# Template register map
Vendor: VendorName Co.Ltd; Series: SeriesName; File version: 1.2
CPU: CM7 r0p1, little endian, MPU, FPU, 4 interrupt priority bits
Registers are 32-bit, read-write, no defined reset value unless marked. A register's access mark holds for its fields unless they carry their own. Offsets are from the block's base; [hi:lo] are bit positions; {n}, {i} and the like mark numbered series; 'fields as' and 'values as' point back to an identical list.

## SDFM1 — Sigma Delta Filter Module 1
Base 0x40014000
Same registers: SDFM2 0x40015000, SDFM3 0x40016000, SDFM4 0x40017000
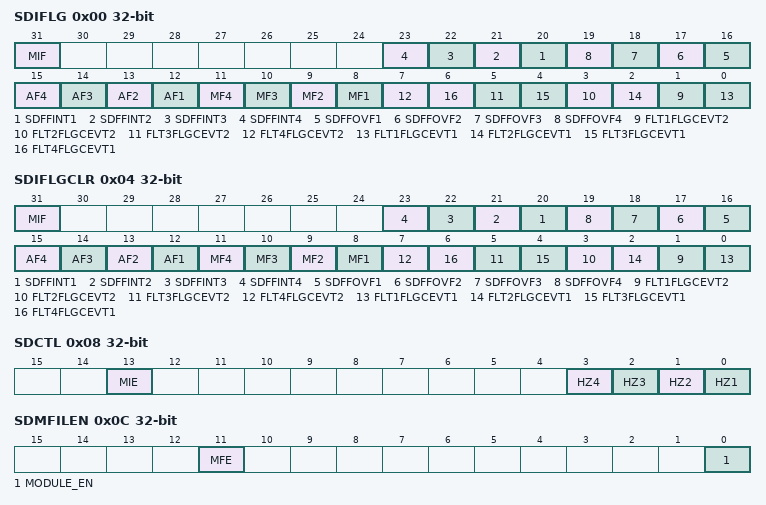
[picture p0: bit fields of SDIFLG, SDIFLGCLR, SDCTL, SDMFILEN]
0x00 SDIFLG ro — SDFM interrupt flag register
  [31] MIF — SDFM MIF bit: set whenever any error interrupt
  [n+19] SDFFINT{n} (n=1..4) — SDFM SDFFINT{n} bit: SDFIFO data ready interrupt for Ch{n}
  [n+15] SDFFOVF{n} (n=1..4) — SDFM SDFFOVF{n} bit: FIFO overflow flag for Ch{n}
  [n+11] AF{n} (n=1..4) — SDFM AF{n} bit: acknowledge flag for filter {n}
  [n+7] MF{n} (n=1..4) — SDFM MF{n} bit: modulator failure for filter {n}
  [2n-1] FLT{n}FLGCEVT2 (n=1..4) — SDFM FLT{n}FLGCEVT2 bit: low-level interrupt flag for Ch{n}
  [2n-2] FLT{n}FLGCEVT1 (n=1..4) — SDFM FLT{n}FLGCEVT1 bit: high-level interrupt flag for Ch{n}
0x04 SDIFLGCLR — SDFM interrupt flag clear register
  [31] MIF — SDFM MIF bit: flag-clear bit for SDFM master interrupt flag
  [n+19] SDFFINT{n} (n=1..4) — SDFM SDFFINT{n} bit: SDFIFO data ready interrupt flag-clear bit for Ch{n}
  [n+15] SDFFOVF{n} (n=1..4) — SDFM SDFFOVF{n} bit: SDFIFO overflow clear Ch{n}
  [n+11] AF{n} (n=1..4) — SDFM AF{n} bit: flag clear bit for acknowledge flag for filter {n}
  [n+7] MF{n} (n=1..4) — SDFM MF{n} bit: flag clear bit for MF{n}
  [2n-1] FLT{n}FLGCEVT2 (n=1..4) — SDFM FLT{n}FLGCEVT2 bit: flag clear bit for IFL{n}
  [2n-2] FLT{n}FLGCEVT1 (n=1..4) — SDFM FLT{n}FLGCEVT1 bit: flag clear bit for IFH{n}
0x08 SDCTL — SDFM control register
  [13] MIE — SDFM MIE bit: master SDy_ERR interrupt enable
  [n-1] HZ{n} (n=1..4) — SDFM HZ{n} bit: flag clear bit for HZ{n}
0x0C SDMFILEN — SDFM master filter enable register
  [11] MFE — SDFM MFE bit: master filter enable
  [0] MODULE_EN — SDFM MODULE_EN bit: input enable signal of module clock and bit stream
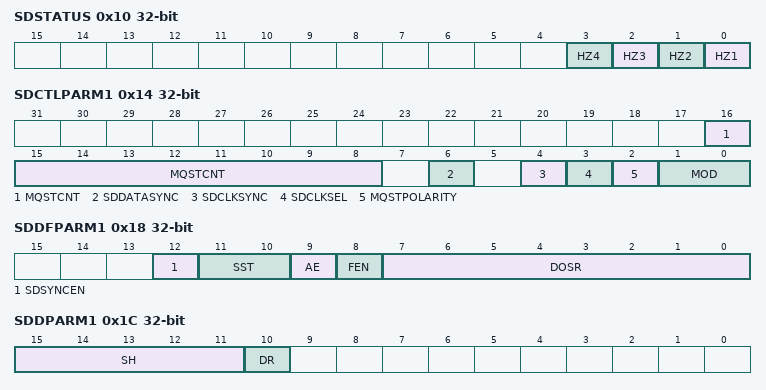
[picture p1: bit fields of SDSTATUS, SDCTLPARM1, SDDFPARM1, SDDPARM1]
0x10 SDSTATUS ro — SDFM status register
  [n-1] HZ{n} (n=1..4) — SDFM HZ{n} bit: high-level threshold crossing flag Ch{n}
0x14 SDCTLPARM1 — SDFM channel 1 parameter control register
  [16:8] MQSTCNT — SDFM MQSTCNT[8:0] bit: specify the maximum value of counter that uses SDFMCLK decoding
  [6] SDDATASYNC — SDFM SDDATASYNC bit: whether modulated bit stream of channel 1 will be filtered to eliminate noise
  [4] SDCLKSYNC — SDFM SDCLKSYNC bit: whether modulated clock of channel 1 will be filtered to eliminate noise
  [3] SDCLKSEL — SDFM SDCLKSEL bit: modulated clock of channel 1 select
  [2] MQSTPOLARITY — SDFM MQSTPOLARITY bit: protocol standard on which Manchester decoding is based
  [1:0] MOD — SDFM MOD[1:0] bit: modulator clock modes
0x18 SDDFPARM1 — SDFM channel 1 data-filter control register
  [12] SDSYNCEN — SDFM SDSYNCEN bit: PWM synchronization of data filter of channel 1
  [11:10] SST — SDFM SST[1:0] bit: data filter structure of channel 1
  [9] AE — SDFM AE bit: data filter acknowledge enable of channel 1
  [8] FEN — SDFM FEN bit: data filter enable of channel 1
  [7:0] DOSR — SDFM DOSR[7:0] bit: data filter oversampling ratio of channel 1
0x1C SDDPARM1 — SDFM channel 1 data-filter paramenter control register
  [15:11] SH — SDFM SH[4:0] bit: shift control of channel 1
  [10] DR — SDFM DR bit: data filter data representation of channel 1
0x20 SDFLT1CMPH1 — SDFM channel 1 high limit register 1
  [14:0] HLT — SDFM HLT[14:0] bit: high limit register 1 compare with the comparator filter of channel 1 output
0x24 SDFLT1CMPL1 — SDFM channel 1 low limit register 1
  [14:0] LLT — SDFM LLT[14:0] bit: low limit register 1 compare with the comparator filter of channel 1 output
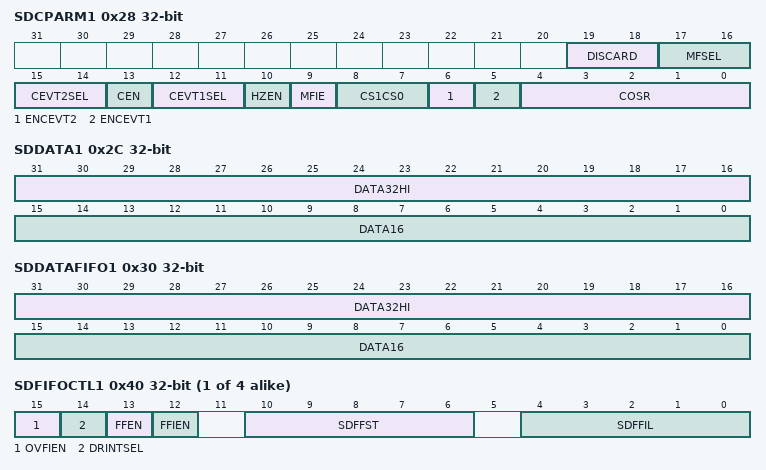
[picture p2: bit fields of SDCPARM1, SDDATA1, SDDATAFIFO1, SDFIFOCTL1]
0x28 SDCPARM1 — SDFM channel 1 comparator filter control register
  [19:18] DISCARD — SDFM DISCARD[1:0] bit: select the first few pieces of data not participating comparation
  [17:16] MFSEL — SDFM MFSEL[1:0] bit: clock not reverse detection window size select
  [15:14] CEVT2SEL — SDFM CEVT2SEL[1:0] bit: comparator filter of channel 1 CEVT2 select
  [13] CEN — SDFM CEN bit: comparator filter of channel 1 enable
  [12:11] CEVT1SEL — SDFM CEVT1SEL[1:0] bit: comparator filter of channel 1 CEVT1 select
  [10] HZEN — SDFM HZEN bit: high level threshold crossing output enable of channel 1
  [9] MFIE — SDFM MFIE bit: modulator failure interrupt enable of channel 1
  [8:7] CS1CS0 — SDFM CS1CS0[1:0] bit: comparator filter of channel 1 structure
  [6] ENCEVT2 — SDFM ENCEVT2 bit: comparator filter of channel 1 CEVT2 interrupt enable
  [5] ENCEVT1 — SDFM ENCEVT1 bit: comparator filter of channel 1 CEVT1 interrupt enable
  [4:0] COSR — SDFM COSR[4:0] bit: comparator oversampling ratio of channel 1
0x2C SDDATA1 ro — SDFM channel 1 data-filter register
  [31:16] DATA32HI — SDFM DATA32HI[15:0] bit: high 16 bit of storing result in 32 bit mode
  [15:0] DATA16 — SDFM DATA16[15:0] bit: low 16 bit of storing result in 32 bit mode
0x30 SDDATAFIFO1 ro — SDFM channel 1 data-fliter FIFO register
  fields as SDDATA1
0x34 SDCDATA1 ro — SDFM channel 1 comparator filter result register
  [15:0] DATA16 — SDFM DATA16[15:0] bit: filtering result of comparator filter of channel 1
{0x0+0x38*i} SDFLT{i}CMPH2 (i=1..4) — SDFM channel {i} high limit register 2
  [14:0] HLT — SDFM HLT[14:0] bit: high limit register 2 compare with the comparator filter of channel {i} output
{0x4+0x38*i} SDFLT{i}CMPHZ (i=1..4) — SDFM channel {i} Z limit register
  [14:0] HLTZ — SDFM HLTZ[14:0] bit: Z limit register compare with the comparator filter of channel {i} output
{0x8+0x38*i} SDFIFOCTL{i} (i=1..4) — SDFM channel {i} data-filter FIFO control register
  [15] OVFIEN — SDFM OVFIEN bit: SDFIFO overflow interrupt enable of channel {i}
  [14] DRINTSEL — SDFM DRINTSEL bit: data-ready interrupt (DRINT) source select of channel {i}
  [13] FFEN — SDFM FFEN bit: SDFIFO enable of channel {i}
  [12] FFIEN — SDFM FFIEN bit: SDFIFO data ready interrupt enable of channel {i}
  [10:6] SDFFST — SDFM SDFFST[4:0] bit: SDFIFO status of channel {i}
  [4:0] SDFFIL — SDFM SDFFIL[4:0] bit: SDFIFO interrupt level bits of channel {i}
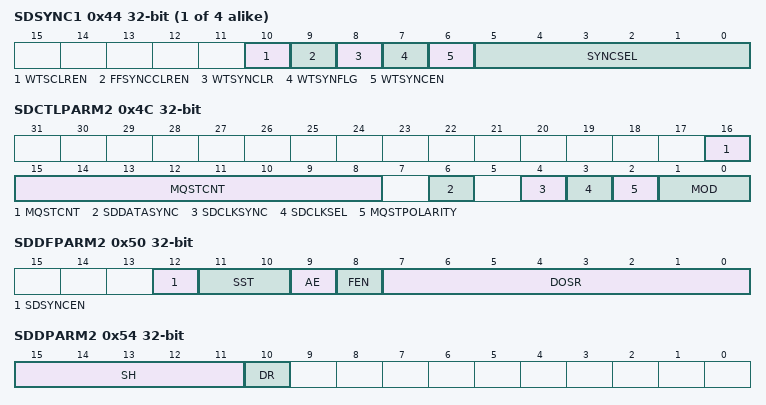
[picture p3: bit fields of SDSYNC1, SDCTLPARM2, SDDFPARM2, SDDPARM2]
{0xC+0x38*i} SDSYNC{i} (i=1..4) — SDFM channel {i} synchronization register
  [10] WTSCLREN — SDFM WTSCLREN bit: WTSYNFLG clear-on-FIFOINT enable of channel {i}
  [9] FFSYNCCLREN — SDFM FFSYNCCLREN bit: FIFO clear-on-SDSYNC enable of channel {i}
  [8] WTSYNCLR — SDFM WTSYNCLR bit: wait-for-sync flag clear
  [7] WTSYNFLG — SDFM WTSYNFLG bit: wait-for-sync flag
  [6] WTSYNCEN — SDFM WTSYNCEN bit: wait-for-sync enable
  [5:0] SYNCSEL — SDFM SYNCSEL[5:0] bit: defines source for the SDSYNC input on channel {i}
{0x10+0x38*i} SDFLT{i}CMPL2 (i=1..4) — SDFM channel {i} low limit register 2
  [14:0] LLT — SDFM LLT[14:0] bit: low limit register 2 compare with the comparator filter of channel {i} output
0x4C SDCTLPARM2 — SDFM channel 2 parameter control register
  [16:8] MQSTCNT — SDFM MQSTCNT[8:0] bit: specify the maximum value of counter that uses SDFMCLK decoding
  [6] SDDATASYNC — SDFM SDDATASYNC bit: whether modulated bit stream of channel 2 will be filtered to eliminate noise
  [4] SDCLKSYNC — SDFM SDCLKSYNC bit: whether modulated clock of channel 2 will be filtered to eliminate noise
  [3] SDCLKSEL — SDFM SDCLKSEL bit: modulated clock of channel 2 select
  [2] MQSTPOLARITY — SDFM MQSTPOLARITY bit: protocol standard on which Manchester decoding is based
  [1:0] MOD — SDFM MOD[1:0] bit: modulator clock modes
0x50 SDDFPARM2 — SDFM channel 2 data-filter control register
  [12] SDSYNCEN — SDFM SDSYNCEN bit: PWM synchronization of data filter of channel 2
  [11:10] SST — SDFM SST[1:0] bit: data filter structure of channel 2
  [9] AE — SDFM AE bit: data filter acknowledge enable of channel 2
  [8] FEN — SDFM FEN bit: data filter enable of channel 2
  [7:0] DOSR — SDFM DOSR[7:0] bit: data filter oversampling ratio of channel 2
0x54 SDDPARM2 — SDFM channel 2 data-filter parameter control register
  [15:11] SH — SDFM SH[4:0] bit: shift control of channel 2
  [10] DR — SDFM DR bit: data filter data representation of channel 2
0x58 SDFLT2CMP1 — SDFM channel 2 high limit register 1
  [14:0] HLT — SDFM HLT[14:0] bit: high limit register 1 compare with the comparator filter of channel 2 output
0x5C SDFLT2CMPL1 — SDFM channel 2 low limit register 1
  [14:0] LLT — SDFM LLT[14:0] bit: low limit register 1 compare with the comparator filter of channel 2 output
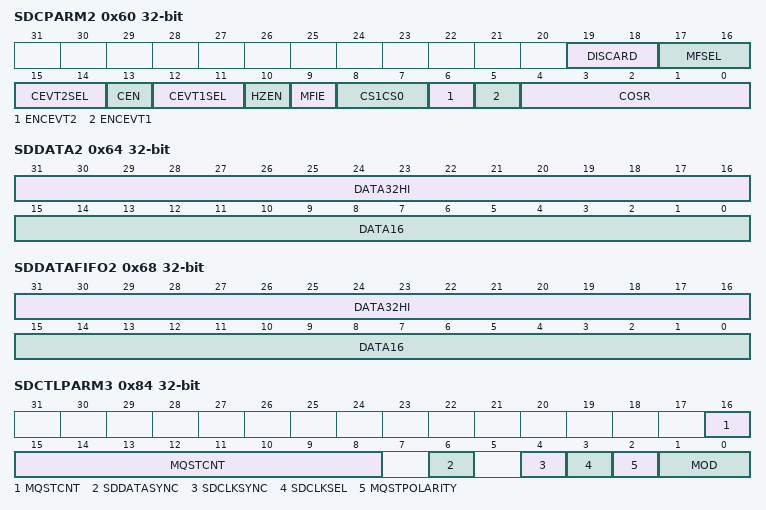
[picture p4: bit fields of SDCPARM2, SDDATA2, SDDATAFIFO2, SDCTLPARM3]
0x60 SDCPARM2 — SDFM channel 2 comparator filter control register
  [19:18] DISCARD — SDFM DISCARD[1:0] bit: select the first few pieces of data not participating comparation
  [17:16] MFSEL — SDFM MFSEL[1:0] bit: clock not reverse detection window size select
  [15:14] CEVT2SEL — SDFM CEVT2SEL[1:0] bit: comparator filter of channel 2 CEVT2 select
  [13] CEN — SDFM CEN bit: comparator filter of channel 2 enable
  [12:11] CEVT1SEL — SDFM CEVT1SEL[1:0] bit: comparator filter of channel 2 CEVT1 select
  [10] HZEN — SDFM HZEN bit: high level threshold crossing output enable of channel 2
  [9] MFIE — SDFM MFIE bit: modulator failure interrupt enable of channel 2
  [8:7] CS1CS0 — SDFM CS1CS0[1:0] bit: comparator filter of channel 2 structure
  [6] ENCEVT2 — SDFM ENCEVT2 bit: comparator filter of channel 2 CEVT2 interrupt enable
  [5] ENCEVT1 — SDFM ENCEVT1 bit: comparator filter of channel 2 CEVT1 interrupt enable
  [4:0] COSR — SDFM COSR[4:0] bit: comparator oversampling ratio of channel 2
0x64 SDDATA2 ro — SDFM channel 2 data-filter register
  fields as SDDATA1
0x68 SDDATAFIFO2 ro — SDFM channel 2 data-fliter FIFO register
  fields as SDDATA1
0x6C SDCDATA2 ro — SDFM channel 2 comparator filter result register
  [15:0] DATA16 — SDFM DATA16[15:0] bit: filtering result of comparator filter of channel 2
0x84 SDCTLPARM3 — SDFM channel 3 parameter control register
  [16:8] MQSTCNT — SDFM MQSTCNT[8:0] bit: specify the maximum value of counter that uses SDFMCLK decoding
  [6] SDDATASYNC — SDFM SDDATASYNC bit: whether modulated bit stream of channel 3 will be filtered to eliminate noise
  [4] SDCLKSYNC — SDFM SDCLKSYNC bit: whether modulated clock of channel 3 will be filtered to eliminate noise
  [3] SDCLKSEL — SDFM SDCLKSEL bit: modulated clock of channel 3 select
  [2] MQSTPOLARITY — SDFM MQSTPOLARITY bit: protocol standard on which Manchester decoding is based
  [1:0] MOD — SDFM MOD[1:0] bit: modulator clock modes
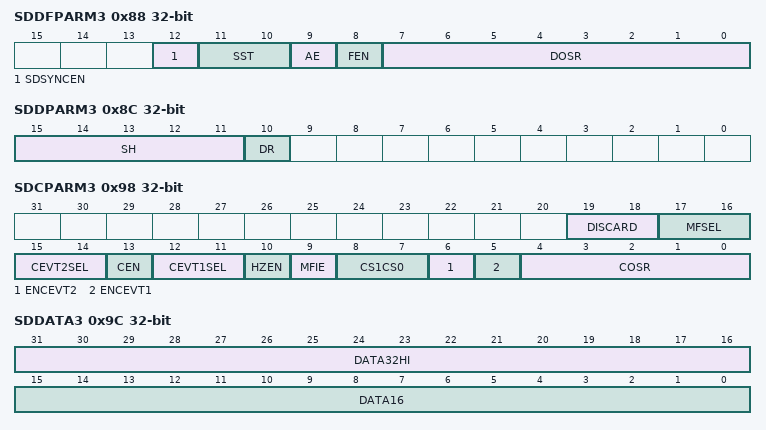
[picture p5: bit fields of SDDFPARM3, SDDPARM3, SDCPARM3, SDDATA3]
0x88 SDDFPARM3 — SDFM channel 3 data-filter control register
  [12] SDSYNCEN — SDFM SDSYNCEN bit: PWM synchronization of data filter of channel 3
  [11:10] SST — SDFM SST[1:0] bit: data filter structure of channel 3
  [9] AE — SDFM AE bit: data filter acknowledge enable of channel 3
  [8] FEN — SDFM FEN bit: data filter enable of channel 3
  [7:0] DOSR — SDFM DOSR[7:0] bit: data filter oversampling ratio of channel 3
0x8C SDDPARM3 — SDFM channel 3 data-filter parameter control register
  [15:11] SH — SDFM SH[4:0] bit: shift control of channel 3
  [10] DR — SDFM DR bit: data filter data representation of channel 3
0x90 SDFLT3CMP1 — SDFM channel 3 high limit register 1
  [14:0] HLT — SDFM HLT[14:0] bit: high limit register 1 compare with the comparator filter of channel 3 output
0x94 SDFLT3CMPL1 — SDFM channel 3 low limit register 1
  [14:0] LLT — SDFM LLT[14:0] bit: low limit register 1 compare with the comparator filter of channel 3 output
0x98 SDCPARM3 — SDFM channel 3 comparator filter control register
  [19:18] DISCARD — SDFM DISCARD[1:0] bit: select the first few pieces of data not participating comparation
  [17:16] MFSEL — SDFM MFSEL[1:0] bit: clock not reverse detection window size select
  [15:14] CEVT2SEL — SDFM CEVT2SEL[1:0] bit: comparator filter of channel 3 CEVT2 select
  [13] CEN — SDFM CEN bit: comparator filter of channel 3 enable
  [12:11] CEVT1SEL — SDFM CEVT1SEL[1:0] bit: comparator filter of channel 3 CEVT1 select
  [10] HZEN — SDFM HZEN bit: high level threshold crossing output enable of channel 3
  [9] MFIE — SDFM MFIE bit: modulator failure interrupt enable of channel 3
  [8:7] CS1CS0 — SDFM CS1CS0[1:0] bit: comparator filter of channel 3 structure
  [6] ENCEVT2 — SDFM ENCEVT2 bit: comparator filter of channel 3 CEVT2 interrupt enable
  [5] ENCEVT1 — SDFM ENCEVT1 bit: comparator filter of channel 3 CEVT1 interrupt enable
  [4:0] COSR — SDFM COSR[4:0] bit: comparator oversampling ratio of channel 3
0x9C SDDATA3 ro — SDFM channel 3 data-filter register
  fields as SDDATA1
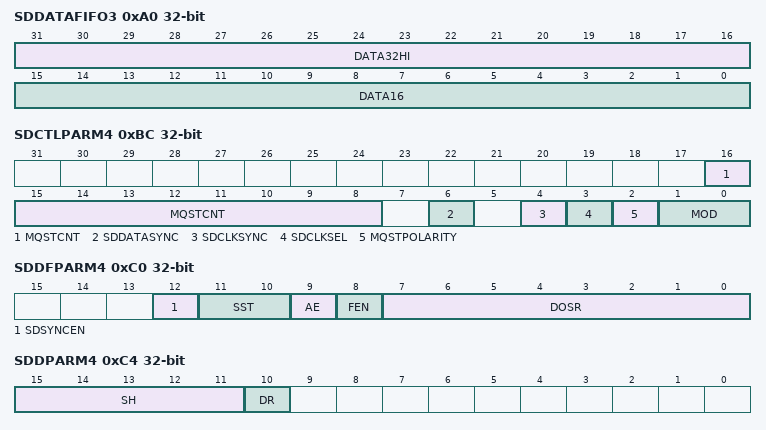
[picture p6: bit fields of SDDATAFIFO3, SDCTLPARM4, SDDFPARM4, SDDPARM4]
0xA0 SDDATAFIFO3 ro — SDFM channel 3 data-fliter FIFO register
  fields as SDDATA1
0xA4 SDCDATA3 ro — SDFM channel 3 comparator filter result register
  [15:0] DATA16 — SDFM DATA16[15:0] bit: filtering result of comparator filter of channel 3
0xBC SDCTLPARM4 — SDFM channel 4 parameter control register
  [16:8] MQSTCNT — SDFM MQSTCNT[8:0] bit: specify the maximum value of counter that uses SDFMCLK decoding
  [6] SDDATASYNC — SDFM SDDATASYNC bit: whether modulated bit stream of channel 4 will be filtered to eliminate noise
  [4] SDCLKSYNC — SDFM SDCLKSYNC bit: whether modulated clock of channel 4 will be filtered to eliminate noise
  [3] SDCLKSEL — SDFM SDCLKSEL bit: modulated clock of channel 4 select
  [2] MQSTPOLARITY — SDFM MQSTPOLARITY bit: protocol standard on which Manchester decoding is based
  [1:0] MOD — SDFM MOD[1:0] bit: modulator clock modes
0xC0 SDDFPARM4 — SDFM channel 4 data-filter control register
  [12] SDSYNCEN — SDFM SDSYNCEN bit: PWM synchronization of data filter of channel 4
  [11:10] SST — SDFM SST[1:0] bit: data filter structure of channel 4
  [9] AE — SDFM AE bit: data filter acknowledge enable of channel 4
  [8] FEN — SDFM FEN bit: data filter enable of channel 4
  [7:0] DOSR — SDFM DOSR[7:0] bit: data filter oversampling ratio of channel 4
0xC4 SDDPARM4 — SDFM channel 4 data-filter parameter control register
  [15:11] SH — SDFM SH[4:0] bit: shift control of channel 4
  [10] DR — SDFM DR bit: data filter data representation of channel 4
0xC8 SDFLT4CMPH1 — SDFM channel 4 high limit register 1
  [14:0] HLT — SDFM HLT[14:0] bit: high limit register 1 compare with the comparator filter of channel 4 output
0xCC SDFLT4CMPL1 — SDFM channel 4 low limit register 1
  [14:0] LLT — SDFM LLT[14:0] bit: low limit register 1 compare with the comparator filter of channel 4 output
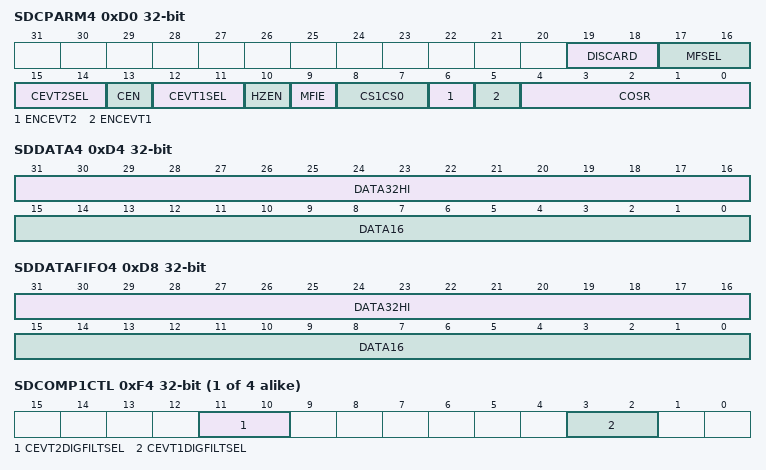
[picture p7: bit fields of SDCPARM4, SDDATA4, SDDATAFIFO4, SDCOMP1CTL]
0xD0 SDCPARM4 — SDFM channel 4 comparator filter control register
  [19:18] DISCARD — SDFM DISCARD[1:0] bit: select the first few pieces of data not participating comparation
  [17:16] MFSEL — SDFM MFSEL[1:0] bit: clock not reverse detection window size select
  [15:14] CEVT2SEL — SDFM CEVT2SEL[1:0] bit: comparator filter of channel 4 CEVT2 select
  [13] CEN — SDFM CEN bit: comparator filter of channel 4 enable
  [12:11] CEVT1SEL — SDFM CEVT1SEL[1:0] bit: comparator filter of channel 4 CEVT1 select
  [10] HZEN — SDFM HZEN bit: high level threshold crossing output enable of channel 4
  [9] MFIE — SDFM MFIE bit: modulator failure interrupt enable of channel 4
  [8:7] CS1CS0 — SDFM CS1CS0[1:0] bit: comparator filter of channel 4 structure
  [6] ENCEVT2 — SDFM ENCEVT2 bit: comparator filter of channel 4 CEVT2 interrupt enable
  [5] ENCEVT1 — SDFM ENCEVT1 bit: comparator filter of channel 4 CEVT1 interrupt enable
  [4:0] COSR — SDFM COSR[4:0] bit: comparator oversampling ratio of channel 4
0xD4 SDDATA4 ro — SDFM channel 4 data-filter register
  fields as SDDATA1
0xD8 SDDATAFIFO4 ro — SDFM channel 4 data-fliter FIFO register
  fields as SDDATA1
0xDC SDCDATA4 ro — SDFM channel 4 comparator filter result register
  [15:0] DATA16 — SDFM DATA16[15:0] bit: filtering result of comparator filter of channel 4
{0xDC+0x18*i} SDCOMP{i}CTL (i=1..4) — SDFM channel {i} comparation event control register
  [11:10] CEVT2DIGFILTSEL — SDFM CEVT2DIGFILTSEL[1:0] bit: CEVT2 output source select of channel {i}
  [3:2] CEVT1DIGFILTSEL — SDFM CEVT1DIGFILTSEL[1:0] bit: CEVT1 output source select of channel {i}
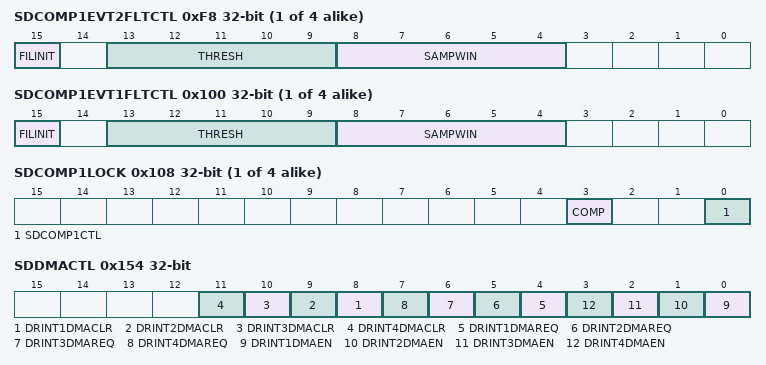
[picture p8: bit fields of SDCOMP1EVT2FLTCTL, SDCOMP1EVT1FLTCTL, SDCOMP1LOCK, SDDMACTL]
{0xE0+0x18*i} SDCOMP{i}EVT2FLTCTL (i=1..4) — SDFM channel {i}'s CEVT2 filtering control register
  [15] FILINIT — SDFM FILINIT bit: CEVT2 filter initialize of channel {i}
  [13:9] THRESH — SDFM THRESH[4:0] bit: CEVT2 filter arbitration threshold of channel {i}
  [8:4] SAMPWIN — SDFM SAMPWIN[4:0] bit: CEVT2 filter window size of channel {i}
{0xE4+0x18*i} SDCOMP{i}EVT2FLTCLKCTL (i=1..4) — SDFM channel {i}'s CEVT2 filtering clock control register
  [9:0] CLKPRESCALE — SDFM CLKPRESCALE[9:0] bit: CEVT2 filter clock prescale of channel {i}
{0xE8+0x18*i} SDCOMP{i}EVT1FLTCTL (i=1..4) — SDFM channel {i}'s CEVT1 filtering control register
  [15] FILINIT — SDFM FILINIT bit: CEVT1 filter initialize of channel {i}
  [13:9] THRESH — SDFM THRESH[4:0] bit: CEVT1 filter arbitration threshold of channel {i}
  [8:4] SAMPWIN — SDFM SAMPWIN[4:0] bit: CEVT1 filter window size of channel {i}
{0xEC+0x18*i} SDCOMP{i}EVT1FLTCLKCTL (i=1..4) — SDFM channel {i}'s CEVT1 filtering clock control register
  [9:0] CLKPRESCALE — SDFM CLKPRESCALE[9:0] bit: CEVT1 filter clock prescale of channel {i}
{0xF0+0x18*i} SDCOMP{i}LOCK (i=1..4) — SDFM channel {i} comparation event lock register
  [3] COMP — SDFM COMP bit: lock writing privilege of SDCOMP{i}EVT1/2FLTCTL and SDCOMP{i}EVT1/2FLTCLKCTL
  [0] SDCOMP1CTL — SDFM SDCOMP1CTL bit: lock writing privilege of SDCOMP{i}CTL
0x154 SDDMACTL — SDFM DMA control register
  [n+7] DRINT{n}DMACLR (n=1..4) — SDFM DRINT{n}DMACLR bit: DMA request flag software clear of DRINT{n}
  [n+3] DRINT{n}DMAREQ ro (n=1..4) — SDFM DRINT{n}DMAREQ bit: DMA request flag when source generating of DRINT{n}
  [n-1] DRINT{n}DMAEN (n=1..4) — SDFM DRINT{n}DMAEN bit: DMA request enable when source generating of DRINT{n}
